# R7FA4T1BB register map
Vendor: Renesas Electronics Corporation; Series: RA4; File version: 1.20.00
CPU: CM33 r0p4, little endian, MPU, FPU, VTOR, 4 interrupt priority bits, 96 interrupts
Registers are 32-bit, read-write, reset 0x0 unless marked. A register's access mark holds for its fields unless they carry their own. Offsets are from the block's base; [hi:lo] are bit positions; {n}, {i} and the like mark numbered series.

## FCACHE — SYSTEM/FLASH
Base 0x4001C100
0x00 FCACHEE 16-bit — Flash Cache Enable Register
  [0] FCACHEEN — Flash Cache Enable
0x04 FCACHEIV 16-bit — Flash Cache Invalidate Register
  [0] FCACHEIV — Flash Cache Invalidate
0x1C FLWT 8-bit — Flash Wait Cycle Register
  [2:0] FLWT — Flash Wait Cycle
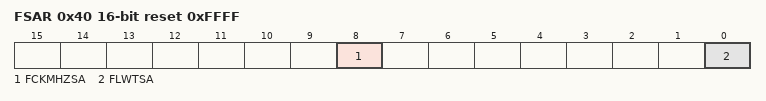
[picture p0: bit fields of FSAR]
0x40 FSAR 16-bit reset 0xFFFF — Flash Security Attribution Register
  [8] FCKMHZSA — FCKMHZ Security Attribution
  [0] FLWTSA — FLWT Security Attribution

## TFU — Trigonometric Function Unit
Base 0x40021000
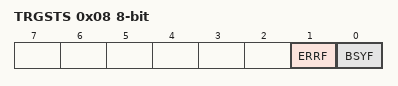
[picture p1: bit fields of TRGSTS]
0x08 TRGSTS 8-bit ro — Trigonometric Status Register
  [1] ERRF — Input error flag
  [0] BSYF — Calculation in progress flag
0x10 SCDT0 — Sine Cosine Data Register 0
  [31:0] SCDT0 — Sine Cosine Data Register 0 (single,precision floating,point)
0x14 SCDT1 — Sine Cosine Data Register 1
  [31:0] SCDT1 — Sine Cosine Data Register 1 (single,precision floating,point)
0x18 ATDT0 — Arctangent Data Register 0
  [31:0] ATDT0 — Arctangent Data Register 0 (single,precision floating,point)
0x1C ATDT1 — Arctangent Data Register 1
  [31:0] ATDT1 — Arctangent Data Register 1 (single,precision floating,point)

## PORT0 — Pmn Pin FunctionPort 0 Control RegistersPmn Pin Function Control Register
Base 0x40080000
Same registers: PORT5 0x400800A0, PORT8 0x40080100
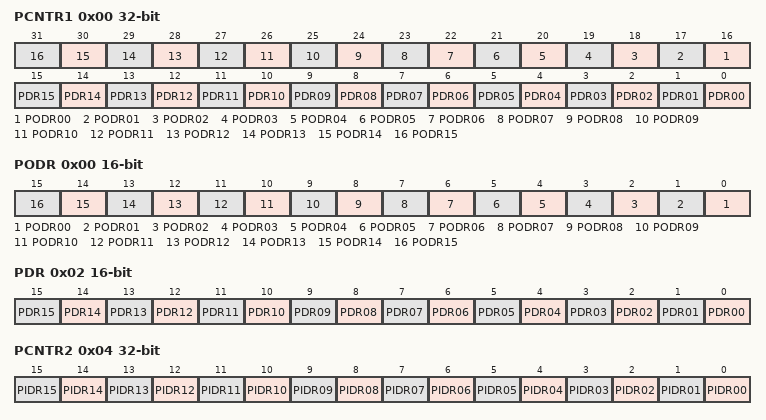
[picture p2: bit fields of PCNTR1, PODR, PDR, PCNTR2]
0x00 PCNTR1 — Port Control Register 1
  [n+16] PODR{n:02} (n=0..15) — Pmn Output Data
  [n] PDR{n:02} (n=0..15) — Pmn Direction
0x00 PODR 16-bit (alternate view of PCNTR1) — Port Control Register 1
  [n] PODR{n:02} (n=0..15) — Pmn Output Data
0x02 PDR 16-bit (alternate view of PCNTR1) — Port Control Register 1
  [n] PDR{n:02} (n=0..15) — Pmn Direction
0x04 PCNTR2 ro (reset mask 0xFFFF0000) — Port Control Register 2
  [n] PIDR{n:02} (n=0..15) — Pmn State
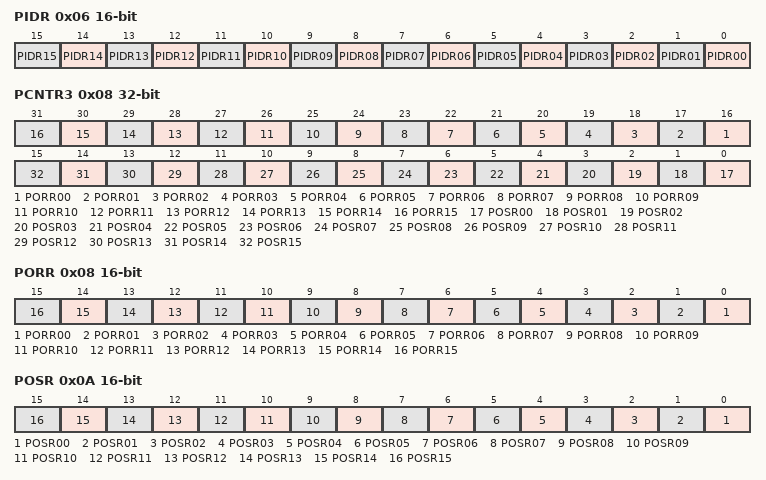
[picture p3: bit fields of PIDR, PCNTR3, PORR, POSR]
0x06 PIDR 16-bit ro reset not defined (alternate view of PCNTR2) — Port Control Register 2
  [n] PIDR{n:02} (n=0..15) — Pmn State
0x08 PCNTR3 wo — Port Control Register 3
  [n+16] PORR{n:02} (n=0..15) — Pmn Output Reset
  [n] POSR{n:02} (n=0..15) — Pmn Output Set
0x08 PORR 16-bit wo (alternate view of PCNTR3) — Port Control Register 3
  [n] PORR{n:02} (n=0..15) — Pmn Output Reset
0x0A POSR 16-bit wo (alternate view of PCNTR3) — Port Control Register 3
  [n] POSR{n:02} (n=0..15) — Pmn Output Set

## PORT1 — Pmn Pin FunctionPort 1 Control RegistersPmn Pin Function Control Register
Base 0x40080020
Same registers: PORT2 0x40080040, PORT3 0x40080060, PORT4 0x40080080
Registers as PORT0; these are added or differ:
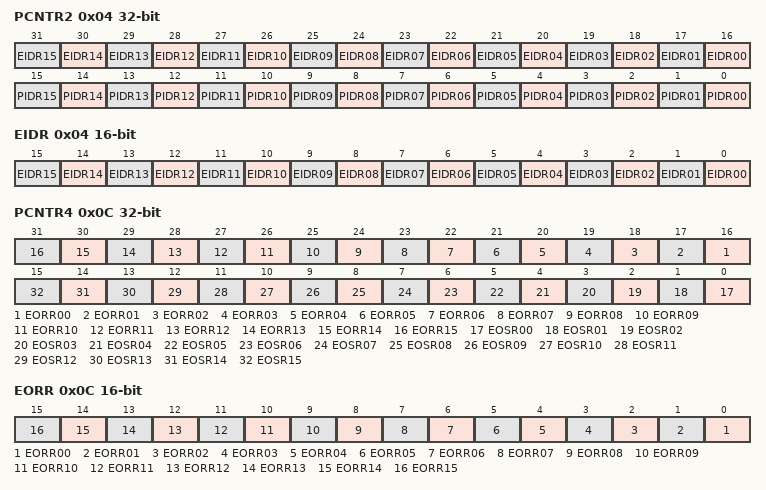
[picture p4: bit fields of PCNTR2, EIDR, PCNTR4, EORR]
0x04 PCNTR2 ro (reset mask 0xFFFF0000) — Port Control Register 2
  [n+16] EIDR{n:02} (n=0..15) — Port Event Input Data
  [n] PIDR{n:02} (n=0..15) — Pmn State
0x04 EIDR 16-bit ro (alternate view of PCNTR2) — Port Control Register 2
  [n] EIDR{n:02} (n=0..15) — Port Event Input Data
0x0C PCNTR4 — Port Control Register 4
  [n+16] EORR{n:02} (n=0..15) — Pmn Event Output Reset
  [n] EOSR{n:02} (n=0..15) — Pmn Event Output Set
0x0C EORR 16-bit (alternate view of PCNTR4) — Port Control Register 4
  [n] EORR{n:02} (n=0..15) — Pmn Event Output Reset
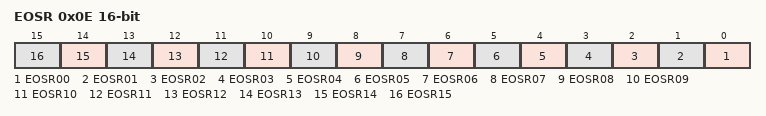
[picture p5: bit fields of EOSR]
0x0E EOSR 16-bit (alternate view of PCNTR4) — Port Control Register 4
  [n] EOSR{n:02} (n=0..15) — Pmn Event Output Set

## ELC — Event Link Controller
Base 0x40082000
0x00 ELCR 8-bit — Event Link Controller Register
  [7] ELCON — All Event Link Enable
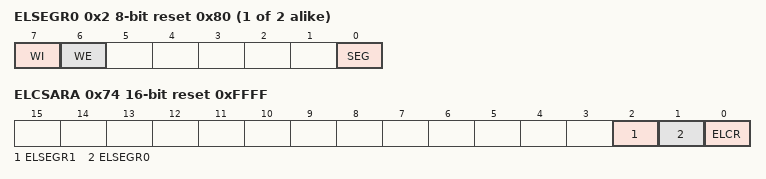
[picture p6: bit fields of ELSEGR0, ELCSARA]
{0x2+2i} ELSEGR{i} (i=0..1) 8-bit reset 0x80 — Event Link Software Event Generation Register {i}
  [7] WI wo — ELSEGR Register Write Disable
  [6] WE — SEG Bit Write Enable
  [0] SEG wo — Software Event Generation
{0x10+4i} ELSR{i} (i=0..9) 16-bit — Event Link Setting Register {i}
  [8:0] ELS — Event Link Select
{0x10+4i} ELSR{i}_1 (i=12..17) 16-bit — Event Link Setting Register {i}
  [8:0] ELS — Event Link Select
0x6C ELSR23 16-bit — Event Link Setting Register 23
  [8:0] ELS — Event Link Select
0x74 ELCSARA 16-bit reset 0xFFFF — Event Link Controller Security Attribution Register A
  [2] ELSEGR1 — Event Link Software Event Generation Register 1 Security Attribution
  [1] ELSEGR0 — Event Link Software Event Generation Register 0 Security Attribution
  [0] ELCR — Event Link Controller Register Security Attribution
0x78 ELCSARB 16-bit reset 0xFFFF — Event Link Controller Security Attribution Register B
  [15:0] ELSR — Event Link Setting Register n Security Attribution
0x7C ELCSARC 16-bit reset 0xFFFF — Event Link Controller Security Attribution Register C
  [7:0] ELSR — Event Link Setting Register n Security Attribution (n = 16 to 23)

## Notices in the file
This software is supplied by Renesas Electronics Corporation and is only intended for
use with Renesas products. No other uses are authorized. This software is owned by
Renesas Electronics Corporation and is protected under all applicable laws, including
copyright laws.
THIS SOFTWARE IS PROVIDED "AS IS" AND RENESAS MAKES NO WARRANTIES REGARDING
THIS SOFTWARE, WHETHER EXPRESS, IMPLIED OR STATUTORY, INCLUDING BUT NOT LIMITED TO
WARRANTIES OF MERCHANTABILITY, FITNESS FOR A PARTICULAR PURPOSE AND NON-INFRINGEMENT.
ALL SUCH WARRANTIES ARE EXPRESSLY DISCLAIMED. TO THE MAXIMUM EXTENT PERMITTED NOT
PROHIBITED BY LAW, NEITHER RENESAS ELECTRONICS CORPORATION NOR ANY OF ITS AFFILIATED
COMPANIES SHALL BE LIABLE FOR ANY DIRECT, INDIRECT, SPECIAL, INCIDENTAL OR CONSEQUENTIAL
DAMAGES FOR ANY REASON RELATED TO THIS SOFTWARE, EVEN IF RENESAS OR ITS AFFILIATES HAVE
BEEN ADVISED OF THE POSSIBILITY OF SUCH DAMAGES.
Renesas reserves the right, without notice, to make changes to this software and to
discontinue the availability of this software. By using this software, you agree to
the additional terms and conditions found by accessing the following link:
http://www.renesas.com/disclaimer
